# S6E1B8xF register map
Vendor: Cypress; File version: 2.0
CPU: CM0PLUS r0p1, little endian, no MPU, no FPU, 2 interrupt priority bits
Registers are 8-bit, read-write, reset 0x0 unless marked. A register's access mark holds for its fields unless they carry their own. Offsets are from the block's base; [hi:lo] are bit positions; {n}, {i} and the like mark numbered series.

## BTIOSEL03 — Base Timer I/O Select
Base 0x40025100
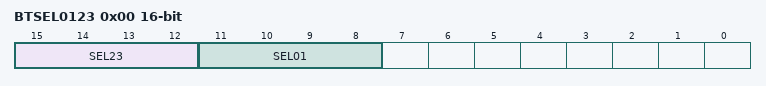
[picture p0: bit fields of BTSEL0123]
0x00 BTSEL0123 16-bit — I/O Select Register
  [15:12] SEL23 — I/O select bits for Ch.2/Ch.3
  [11:8] SEL01 — I/O select bits for Ch.0/Ch.1

## BTIOSEL47 — Base Timer I/O Select
Base 0x40025300
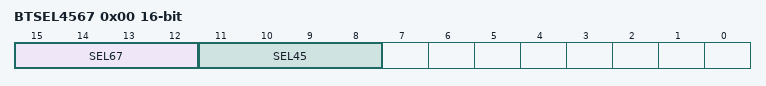
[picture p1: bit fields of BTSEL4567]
0x00 BTSEL4567 16-bit — I/O Select Register
  [15:12] SEL67 — I/O select bits for Ch.6/Ch.7
  [11:8] SEL45 — I/O select bits for Ch.4/Ch.5

## SBSSR — Software-based Simultaneous Startup Register
Base 0x40025F00
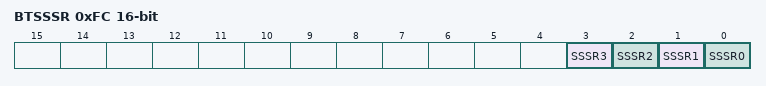
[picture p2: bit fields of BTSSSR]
0xFC BTSSSR 16-bit wo — Software-based Simultaneous Startup Register
  [3] SSSR3 — Software-based simultaneous startup bit of Ch.3
  [2] SSSR2 — Software-based simultaneous startup bit of Ch.2
  [1] SSSR1 — Software-based simultaneous startup bit of Ch.1
  [0] SSSR0 — Software-based simultaneous startup bit of Ch.0

## CRTRIM — CR Trimming Registers
Base 0x4002E000
0x00 MCR_PSR reset 0x1 — High-speed CR Oscillation Frequency Division Setup Register
  [2:0] CSR — High-speed CR oscillation frequency division ratio setting bits
0x04 MCR_FTRM 16-bit reset 0x1EF — High-speed CR Oscillation Frequency Trimming Register
  [9:0] TRD — Frequency trimming setup bits
0x08 MCR_TTRM reset 0x3F — High-speed CR Oscillation Temperature Trimming Setup Register
  [6:0] TRT — Temperature trimming setup bits
0x0C MCR_RLR 32-bit reset 0x1 — High-Speed CR Oscillation Register Write-Protect Register
  [31:0] TRMLCK — Register write-protect bits

## LCDC — LCD Controller
Base 0x40032000
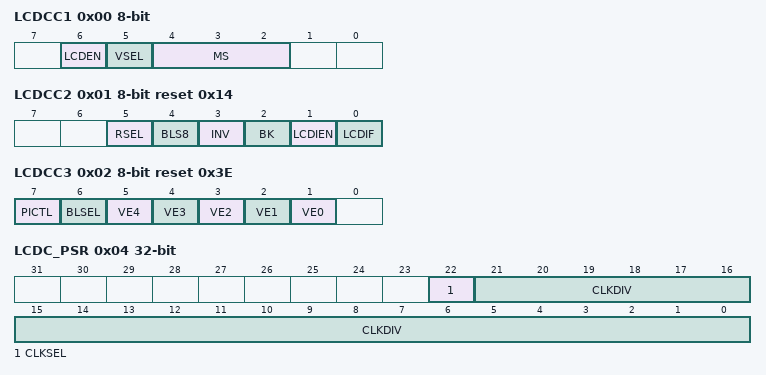
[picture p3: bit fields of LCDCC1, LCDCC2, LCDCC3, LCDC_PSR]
0x00 LCDCC1 — LCDC Control Register 1
  [6] LCDEN — Timer mode operation enable bit
  [5] VSEL — LCD drive power control bit
  [4:2] MS — LCD controller display mode selection bits
0x01 LCDCC2 reset 0x14 — LCDC Control Register 2
  [5] RSEL — Divider resistor value selection bit
  [4] BLS8 — 8 COM mode bias selection bit
  [3] INV — Reverse display control bit
  [2] BK — Blank display control bit
  [1] LCDIEN — Interrupt enable bit
  [0] LCDIF — Interrupt request detection bit
0x02 LCDCC3 reset 0x3E — LCDC Control Register 3
  [7] PICTL — I/O port input control bit
  [6] BLSEL — Blink interval selection bit
  [n+1] VE{n} (n=0..4) — VV{n} selection bit
0x04 LCDC_PSR 32-bit — LCDC Clock Prescaler Register
  [22] CLKSEL — Source clock selection bit
  [21:0] CLKDIV — LCDC clock division ratio setting bits
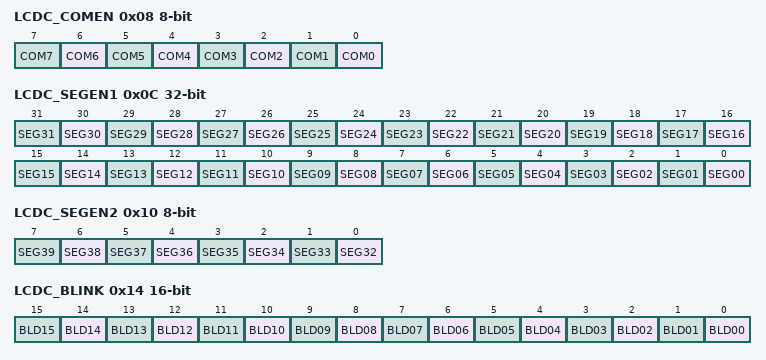
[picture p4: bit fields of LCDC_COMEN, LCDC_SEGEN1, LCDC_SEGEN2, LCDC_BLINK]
0x08 LCDC_COMEN — LCDC COM Output Enable Register
  [n] COM{n} (n=4..7) — Dual purpose COM/SEG port control bits
  [n] COM{n} (n=0..3) — Dual purpose COM port control bit
0x0C LCDC_SEGEN1 32-bit — LCDC SEG Output Enable Register 1
  [n] SEG{n:02} (n=0..31) — Segment {n}
0x10 LCDC_SEGEN2 — LCDC SEG Output Enable Register 2
  [n-32] SEG{n} (n=32..39) — Segment {n}
0x14 LCDC_BLINK 16-bit — LCDC Blink Setting Register
  [n] BLD{n:02} (n=0..15) — Blink operation control bit {n}
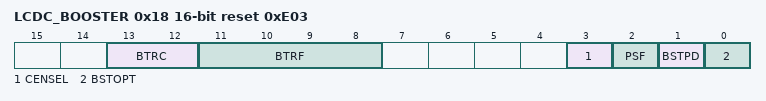
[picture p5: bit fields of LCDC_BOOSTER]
0x18 LCDC_BOOSTER 16-bit reset 0xE03 — LCDC Booster Control Register
  [13:12] BTRC — Booster coarse setting bits for reference voltage of VV1
  [11:8] BTRF — Booster fine setting bits for reference voltage of VV1
  [3] CENSEL — Booster C1/C0 pin enable control
  [2] PSF ro — LCDC power source flag big
  [1] BSTPD — Booster Power down control bit
  [0] BSTOPT — Booster module option
{0x1C+i} LCDRAM{i:02} (i=0..39) — Display Data Memory Register {i:02}

## HDMICEC0 — HDMI-CEC ch.0
Base 0x40034000
Same registers: HDMICEC1 0x40034100
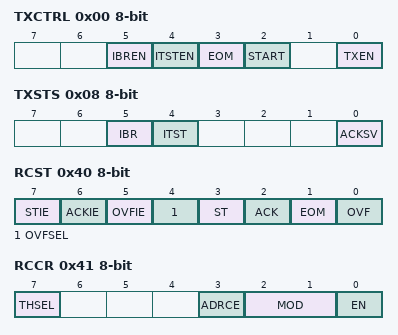
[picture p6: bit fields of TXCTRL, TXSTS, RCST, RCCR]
0x00 TXCTRL — Transmission Control Register
  [5] IBREN — Bus error detection interrupt enable bit
  [4] ITSTEN — transmission status interrupt enable bit
  [3] EOM — EOM setting bit
  [2] START — START setting bit
  [0] TXEN — Transmission operation enable bit
0x04 TXDATA — Transmission Data Register
  [7:0] TXDATA — Transmission Data
0x08 TXSTS — Transmission Status Register
  [5] IBR — Bus error detection interrupt request bit
  [4] ITST — Transmission status interrupt request bit
  [0] ACKSV ro — ACK cycle value bit
0x0C SFREE — Signal Free Time Setting Register
  [3:0] SFREE — Signal free time setting bits
0x40 RCST — Reception Interrupt Control Register
  [7] STIE — Start bit interrupt enable bit
  [6] ACKIE — ACK interrupt enable bit
  [5] OVFIE — Counter overflow interrupt enable bit
  [4] OVFSEL — Counter overflow detection condition setting bit
  [3] ST — Start bit detection bit
  [2] ACK — ACK: ACK detection bit
  [1] EOM — EOM detection bit
  [0] OVF — Counter overflow detection bit
0x41 RCCR — Reception Control Register
  [7] THSEL — Threshold selection bit
  [3] ADRCE — Address comparison enable bit
  [2:1] MOD — Operation mode setting bits
  [0] EN — Operation enable bit
0x44 RCDAHW — "H" Width Setting Register A
0x45 RCSHW — Start Bit "H" Width Setting Register
0x49 RCDBHW — "H" Width Setting Register B
0x4C RCADR2 (reset mask 0x1F) — Device Address Setting Register 2
0x4D RCADR1 (reset mask 0x1F) — Device Address Setting Register 1
0x50 RCDTHL ro — Data Save Register (High-Low)
0x51 RCDTHH ro — Data Save Register (High-High)
0x54 RCDTLL ro — Data Save Register (Low-Low)
0x55 RCDTLH ro — Data Save Register (Low-High)
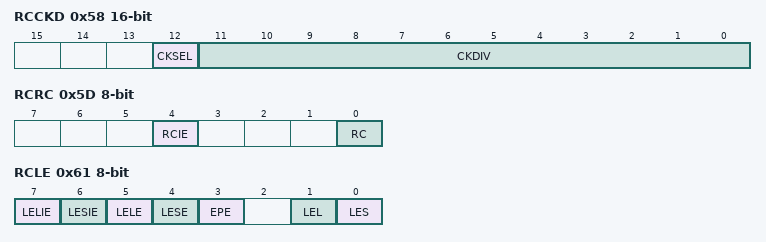
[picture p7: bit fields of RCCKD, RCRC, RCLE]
0x58 RCCKD 16-bit — Clock Division Setting Register
  [12] CKSEL — Operating clock selection bit
  [11:0] CKDIV — Operating clock division setting bits
0x5C RCRHW — Repeat Code "H" Width Setting Register
0x5D RCRC — Repeat Code Interrupt Control Register
  [4] RCIE — Repeat Code Interrupt enable bit
  [0] RC — Repeat code detection flag bit
0x61 RCLE — Data Bit Width Violation Control Register
  [7] LELIE — Maximum data bit width violation interrupt enable bit
  [6] LESIE — Minimum data bit width violation interrupt enable bit
  [5] LELE — Maximum data bit width violation detection enable bit
  [4] LESE — Minimum data bit width violation detection enable bit
  [3] EPE — Error pulse output enable bit
  [1] LEL — Maximum data bit width violation detection flag bit
  [0] LES — Minimum data bit width violation detection flag bit
0x64 RCLESW — Minimum Data Bit Width Setting Register
0x65 RCLELW — Maximum Data Bit Width Setting Register

## Notices in the file
Copyright (C) 2013-2015, Cypress Semiconductor Corporation. All Rights Reserved.
This software, including source code, documentation and related
materials ( "Software" ), is owned by Cypress Semiconductor
Corporation ( "Cypress" ) and is protected by and subject to worldwide
patent protection (United States and foreign), United States copyright
laws and international treaty provisions. Therefore, you may use this
Software only as provided in the license agreement accompanying the
software package from which you obtained this Software ( "EULA" ).
If no EULA applies, Cypress hereby grants you a personal, nonexclusive,
non-transferable license to copy, modify, and compile the
Software source code solely for use in connection with Cypress's
integrated circuit products. Any reproduction, modification, translation,
compilation, or representation of this Software except as specified
above is prohibited without the express written permission of Cypress.
Disclaimer: THIS SOFTWARE IS PROVIDED AS-IS, WITH NO
WARRANTY OF ANY KIND, EXPRESS OR IMPLIED, INCLUDING,
BUT NOT LIMITED TO, NONINFRINGEMENT, IMPLIED
WARRANTIES OF MERCHANTABILITY AND FITNESS FOR A
PARTICULAR PURPOSE. Cypress reserves the right to make
changes to the Software without notice. Cypress does not assume any
liability arising out of the application or use of the Software or any
product or circuit described in the Software. Cypress does not
authorize its products for use in any products where a malfunction or
failure of the Cypress product may reasonably be expected to result in
significant property damage, injury or death ( "High Risk Product" ). By
including Cypress's product in a High Risk Product, the manufacturer
of such system or application assumes all risk of such use and in doing
so agrees to indemnify Cypress against all liability.
